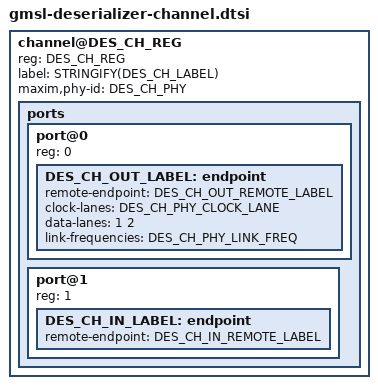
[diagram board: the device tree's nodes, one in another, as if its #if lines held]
// SPDX-License-Identifier: GPL-2.0
/*
 * Copyright (C) 2023 Analog Devices Inc.
 */

#if defined(DES_CH_INDEX)
#define DES_CH_REG DES_CH_INDEX
#define DES_CH_LABEL DES_CH_Y_LABEL(DES_CH_INDEX)
#define DES_CH_OUT_LABEL DES_CH_Y_OUT_LABEL(DES_CH_INDEX)
#define DES_CH_IN_LABEL DES_CH_Y_IN_LABEL(DES_CH_INDEX)
#endif

#if defined(SER_INDEX) && defined(SER_CH_INDEX)
#define DES_CH_IN_REMOTE_LABEL SER_X_CH_Y_OUT_LABEL(SER_INDEX, SER_CH_INDEX)
#endif

#if defined(CSI_INDEX)
#define DES_CH_OUT_REMOTE_LABEL CSI_X_IN_LABEL(CSI_INDEX)
#endif

#if !defined(DES_CH_PHY)
#error
#endif

#if !defined(DES_CH_PHY_NUM_LANES)
#error
#endif

#if !defined(DES_CH_REG)
#error
#endif

#if !defined(DES_CH_OUT_LABEL)
#error
#endif

#if !defined(DES_CH_IN_LABEL)
#error
#endif

#if !defined(DES_CH_OUT_REMOTE_LABEL)
#error
#endif

#if !defined(DES_CH_IN_REMOTE_LABEL)
#error
#endif

#if !defined(DES_CH_PHY_LINK_FREQ)
#error
#endif

#if !defined(DES_CH_PHY_CLOCK_LANE)
#if defined(GMSL_DES_PHY_1_2_LANE_MODE_IN_4_LANES) && DES_CH_PHY == 1
#define DES_CH_PHY_CLOCK_LANE 5
#else
#define DES_CH_PHY_CLOCK_LANE 0
#endif
#endif

channel@DES_CH_REG {
	reg = <DES_CH_REG>;

	label = STRINGIFY(DES_CH_LABEL);

	maxim,phy-id = <DES_CH_PHY>;

	ports {
		#address-cells = <1>;
		#size-cells = <0>;

		port@0 {
			reg = <0>;

			DES_CH_OUT_LABEL: endpoint {
				remote-endpoint = <&DES_CH_OUT_REMOTE_LABEL>;
				clock-lanes = <DES_CH_PHY_CLOCK_LANE>;
#if DES_CH_PHY_NUM_LANES == 2
				data-lanes = <1 2>;
#elif DES_CH_PHY_NUM_LANES == 4
				data-lanes = <1 2 3 4>;
#else
#error
#endif
				link-frequencies = /bits/ 64 <DES_CH_PHY_LINK_FREQ>;
			};
		};

		port@1 {
			reg = <1>;

			DES_CH_IN_LABEL: endpoint {
				remote-endpoint = <&DES_CH_IN_REMOTE_LABEL>;
			};
		};
	};
};

#undef DES_CH_INDEX
#undef SER_INDEX
#undef SER_CH_INDEX
#undef CSI_INDEX
#undef DES_CH_PHY
#undef DES_CH_PHY_NUM_LANES
#undef DES_CH_PHY_CLOCK_LANE
#undef DES_CH_REG
#undef DES_CH_OUT_LABEL
#undef DES_CH_IN_LABEL
#undef DES_CH_OUT_REMOTE_LABEL
#undef DES_CH_IN_REMOTE_LABEL
